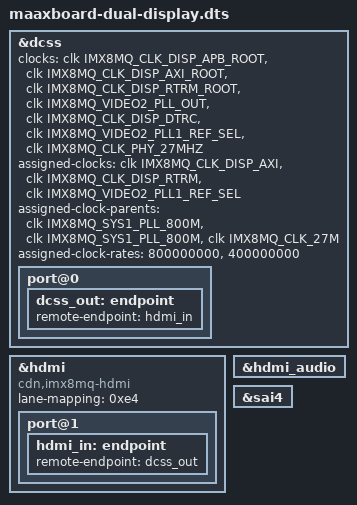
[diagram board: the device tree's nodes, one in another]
/*
 * Copyright 2019 EMBEST
 *
 * This program is free software; you can redistribute it and/or
 * modify it under the terms of the GNU General Public License
 * as published by the Free Software Foundation; either version 2
 * of the License, or (at your option) any later version.
 *
 * This program is distributed in the hope that it will be useful,
 * but WITHOUT ANY WARRANTY; without even the implied warranty of
 * MERCHANTABILITY or FITNESS FOR A PARTICULAR PURPOSE.  See the
 * GNU General Public License for more details.
 */

#include "maaxboard-lcdif-mipi.dts"

/* add hdmi to dual display */
&dcss {
	status = "okay";

	clocks = <&clk IMX8MQ_CLK_DISP_APB_ROOT>,
		 <&clk IMX8MQ_CLK_DISP_AXI_ROOT>,
		 <&clk IMX8MQ_CLK_DISP_RTRM_ROOT>,
		 <&clk IMX8MQ_VIDEO2_PLL_OUT>,
		 <&clk IMX8MQ_CLK_DISP_DTRC>,
		 <&clk IMX8MQ_VIDEO2_PLL1_REF_SEL>,
		 <&clk IMX8MQ_CLK_PHY_27MHZ>;
	clock-names = "apb", "axi", "rtrm", "pix", "dtrc", "pll_src",
				  "pll_phy_ref";
	assigned-clocks = <&clk IMX8MQ_CLK_DISP_AXI>,
			  <&clk IMX8MQ_CLK_DISP_RTRM>,
			  <&clk IMX8MQ_VIDEO2_PLL1_REF_SEL>;
	assigned-clock-parents = <&clk IMX8MQ_SYS1_PLL_800M>,
				 <&clk IMX8MQ_SYS1_PLL_800M>,
				 <&clk IMX8MQ_CLK_27M>;
	assigned-clock-rates = <800000000>,
				   <400000000>;

	port@0 {
		dcss_out: endpoint {
			  remote-endpoint = <&hdmi_in>;
		};
	};
};

&hdmi {
	compatible = "cdn,imx8mq-hdmi";
	lane-mapping = <0xe4>;
	status = "okay";

	port@1 {
		hdmi_in: endpoint {
			remote-endpoint = <&dcss_out>;
		};
	};
};

&hdmi_audio {
	status = "okay";
};

&sai4 {
	status = "okay";
};
